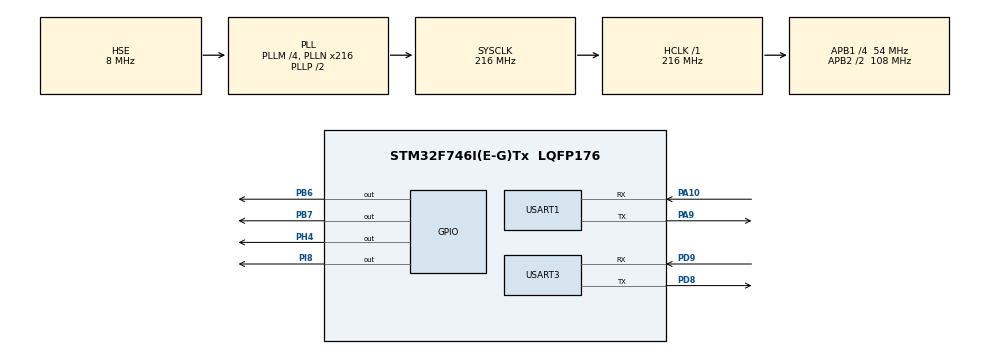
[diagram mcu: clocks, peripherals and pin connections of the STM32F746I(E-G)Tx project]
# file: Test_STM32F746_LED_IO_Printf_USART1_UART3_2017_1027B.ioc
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Mcu.Family=STM32F7
Mcu.Name=STM32F746I(E-G)Tx
Mcu.Package=LQFP176
NVIC.PriorityGroup=NVIC_PRIORITYGROUP_4
NVIC.USART3_IRQn=true\:0\:0\:false\:false\:true
PA10.Mode=Asynchronous
PA10.Signal=USART1_RX
PA9.Mode=Asynchronous
PA9.Signal=USART1_TX
PB6.Signal=GPIO_Output
PB7.Signal=GPIO_Output
PD8.Mode=Asynchronous
PD8.Signal=USART3_TX
PD9.Mode=Asynchronous
PD9.Signal=USART3_RX
PH0/OSC_IN.Mode=HSE-External-Oscillator
PH0/OSC_IN.Signal=RCC_OSC_IN
PH1/OSC_OUT.Mode=HSE-External-Oscillator
PH1/OSC_OUT.Signal=RCC_OSC_OUT
PH4.Signal=GPIO_Output
PI8.Signal=GPIO_Output
ProjectManager.HeapSize=0x200
ProjectManager.StackSize=0x400
ProjectManager.TargetToolchain=EWARM
RCC.AHBFreq_Value=216000000
RCC.APB1CLKDivider=RCC_HCLK_DIV4
RCC.APB1Freq_Value=54000000
RCC.APB1TimFreq_Value=108000000
RCC.APB2CLKDivider=RCC_HCLK_DIV2
RCC.APB2Freq_Value=108000000
RCC.APB2TimFreq_Value=216000000
RCC.CortexFreq_Value=216000000
RCC.HCLKFreq_Value=216000000
RCC.HSE_VALUE=8000000
RCC.HSI_VALUE=16000000
RCC.LSE_VALUE=32768
RCC.PLLM=4
RCC.PLLN=216
RCC.PLLSourceVirtual=RCC_PLLSOURCE_HSE
RCC.SYSCLKFreq_VALUE=216000000
RCC.SYSCLKSource=RCC_SYSCLKSOURCE_PLLCLK
RCC.USBFreq_Value=216000000
RCC.VCOOutputFreq_Value=432000000
USART1.VirtualMode-Asynchronous=VM_ASYNC
USART1.WordLength=WORDLENGTH_8B
USART3.VirtualMode-Asynchronous=VM_ASYNC
USART3.WordLength=WORDLENGTH_8B
board=Test_STM32F746_LED_IO_Printf_USART1_UART3_2017_1027B

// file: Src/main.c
/**
  ******************************************************************************
  * File Name          : main.c
  * Description        : Main program body
  ******************************************************************************
  ** This notice applies to any and all portions of this file
  * that are not between comment pairs USER CODE BEGIN and
  * USER CODE END. Other portions of this file, whether
  * inserted by the user or by software development tools
  * are owned by their respective copyright owners.
  *
  * COPYRIGHT(c) 2017 STMicroelectronics
  *
  * Redistribution and use in source and binary forms, with or without modification,
  * are permitted provided that the following conditions are met:
  *   1. Redistributions of source code must retain the above copyright notice,
  *      this list of conditions and the following disclaimer.
  *   2. Redistributions in binary form must reproduce the above copyright notice,
  *      this list of conditions and the following disclaimer in the documentation
  *      and/or other materials provided with the distribution.
  *   3. Neither the name of STMicroelectronics nor the names of its contributors
  *      may be used to endorse or promote products derived from this software
  *      without specific prior written permission.
  *
  * THIS SOFTWARE IS PROVIDED BY THE COPYRIGHT HOLDERS AND CONTRIBUTORS "AS IS"
  * AND ANY EXPRESS OR IMPLIED WARRANTIES, INCLUDING, BUT NOT LIMITED TO, THE
  * IMPLIED WARRANTIES OF MERCHANTABILITY AND FITNESS FOR A PARTICULAR PURPOSE ARE
  * DISCLAIMED. IN NO EVENT SHALL THE COPYRIGHT HOLDER OR CONTRIBUTORS BE LIABLE
  * FOR ANY DIRECT, INDIRECT, INCIDENTAL, SPECIAL, EXEMPLARY, OR CONSEQUENTIAL
  * DAMAGES (INCLUDING, BUT NOT LIMITED TO, PROCUREMENT OF SUBSTITUTE GOODS OR
  * SERVICES; LOSS OF USE, DATA, OR PROFITS; OR BUSINESS INTERRUPTION) HOWEVER
  * CAUSED AND ON ANY THEORY OF LIABILITY, WHETHER IN CONTRACT, STRICT LIABILITY,
  * OR TORT (INCLUDING NEGLIGENCE OR OTHERWISE) ARISING IN ANY WAY OUT OF THE USE
  * OF THIS SOFTWARE, EVEN IF ADVISED OF THE POSSIBILITY OF SUCH DAMAGE.
  *
  ******************************************************************************
  */
#include "main.h"
#include "stm32f7xx_hal.h"

UART_HandleTypeDef huart1;
UART_HandleTypeDef huart3;

/* USER CODE BEGIN PV */
/* Private variables ---------------------------------------------------------*/

/* USER CODE END PV */

void SystemClock_Config(void);
static void MX_GPIO_Init(void);
static void MX_USART1_UART_Init(void);
static void MX_USART3_UART_Init(void);

/* USER CODE BEGIN PFP */
/* Private function prototypes -----------------------------------------------*/

/* USER CODE END PFP */

int main(void)
{

  /* MCU Configuration----------------------------------------------------------*/

  /* Reset of all peripherals, Initializes the Flash interface and the Systick. */
  HAL_Init();

  /* Configure the system clock */
  SystemClock_Config();

  /* Initialize all configured peripherals */
  MX_GPIO_Init();
  MX_USART1_UART_Init();
  MX_USART3_UART_Init();

  /* Infinite loop */
  while (1)
  {

  /* USER CODE BEGIN 3 */
  	  #if 0		//LJH
		HAL_GPIO_TogglePin(GPIOB,GPIO_PIN_6);
		HAL_Delay(200);
		HAL_GPIO_TogglePin(GPIOB,GPIO_PIN_7);
		HAL_Delay(200);
		HAL_GPIO_TogglePin(GPIOH,GPIO_PIN_4);
		HAL_Delay(200);
		HAL_GPIO_TogglePin(GPIOI,GPIO_PIN_8);
		HAL_Delay(200);
		//printf("Hello World-LJH\r\n");
	#endif

  }
  /* USER CODE END 3 */

}

/** System Clock Configuration
*/
void SystemClock_Config(void)
{

  RCC_OscInitTypeDef RCC_OscInitStruct;
  RCC_ClkInitTypeDef RCC_ClkInitStruct;
  RCC_PeriphCLKInitTypeDef PeriphClkInitStruct;

    /**Configure the main internal regulator output voltage
    */
  __HAL_RCC_PWR_CLK_ENABLE();

  __HAL_PWR_VOLTAGESCALING_CONFIG(PWR_REGULATOR_VOLTAGE_SCALE1);

    /**Initializes the CPU, AHB and APB busses clocks
    */
  RCC_OscInitStruct.OscillatorType = RCC_OSCILLATORTYPE_HSE;
  RCC_OscInitStruct.HSEState = RCC_HSE_ON;
  RCC_OscInitStruct.PLL.PLLState = RCC_PLL_ON;
  RCC_OscInitStruct.PLL.PLLSource = RCC_PLLSOURCE_HSE;
  RCC_OscInitStruct.PLL.PLLM = 4;
  RCC_OscInitStruct.PLL.PLLN = 216;
  RCC_OscInitStruct.PLL.PLLP = RCC_PLLP_DIV2;
  RCC_OscInitStruct.PLL.PLLQ = 2;
  if (HAL_RCC_OscConfig(&RCC_OscInitStruct) != HAL_OK)
  {
    _Error_Handler(__FILE__, __LINE__);
  }

    /**Activate the Over-Drive mode
    */
  if (HAL_PWREx_EnableOverDrive() != HAL_OK)
  {
    _Error_Handler(__FILE__, __LINE__);
  }

    /**Initializes the CPU, AHB and APB busses clocks
    */
  RCC_ClkInitStruct.ClockType = RCC_CLOCKTYPE_HCLK|RCC_CLOCKTYPE_SYSCLK
                              |RCC_CLOCKTYPE_PCLK1|RCC_CLOCKTYPE_PCLK2;
  RCC_ClkInitStruct.SYSCLKSource = RCC_SYSCLKSOURCE_PLLCLK;
  RCC_ClkInitStruct.AHBCLKDivider = RCC_SYSCLK_DIV1;
  RCC_ClkInitStruct.APB1CLKDivider = RCC_HCLK_DIV4;
  RCC_ClkInitStruct.APB2CLKDivider = RCC_HCLK_DIV2;

  if (HAL_RCC_ClockConfig(&RCC_ClkInitStruct, FLASH_LATENCY_7) != HAL_OK)
  {
    _Error_Handler(__FILE__, __LINE__);
  }

  PeriphClkInitStruct.PeriphClockSelection = RCC_PERIPHCLK_USART1|RCC_PERIPHCLK_USART3;
  PeriphClkInitStruct.Usart1ClockSelection = RCC_USART1CLKSOURCE_PCLK2;
  PeriphClkInitStruct.Usart3ClockSelection = RCC_USART3CLKSOURCE_PCLK1;
  if (HAL_RCCEx_PeriphCLKConfig(&PeriphClkInitStruct) != HAL_OK)
  {
    _Error_Handler(__FILE__, __LINE__);
  }

    /**Configure the Systick interrupt time
    */
  HAL_SYSTICK_Config(HAL_RCC_GetHCLKFreq()/1000);

    /**Configure the Systick
    */
  HAL_SYSTICK_CLKSourceConfig(SYSTICK_CLKSOURCE_HCLK);

  /* SysTick_IRQn interrupt configuration */
  HAL_NVIC_SetPriority(SysTick_IRQn, 0, 0);
}

/* USART1 init function */
static void MX_USART1_UART_Init(void)
{

  huart1.Instance = USART1;
  huart1.Init.BaudRate = 115200;
  huart1.Init.WordLength = UART_WORDLENGTH_8B;
  huart1.Init.StopBits = UART_STOPBITS_1;
  huart1.Init.Parity = UART_PARITY_NONE;
  huart1.Init.Mode = UART_MODE_TX_RX;
  huart1.Init.HwFlowCtl = UART_HWCONTROL_NONE;
  huart1.Init.OverSampling = UART_OVERSAMPLING_16;
  huart1.Init.OneBitSampling = UART_ONE_BIT_SAMPLE_DISABLE;
  huart1.AdvancedInit.AdvFeatureInit = UART_ADVFEATURE_NO_INIT;
  if (HAL_UART_Init(&huart1) != HAL_OK)
  {
    _Error_Handler(__FILE__, __LINE__);
  }
  #if 1	//LJH
	 HAL_NVIC_SetPriority(USART1_IRQn, 0, 0);
   	HAL_NVIC_EnableIRQ(USART1_IRQn);
   	__HAL_UART_ENABLE_IT(&huart1,UART_IT_RXNE); // rx  on
  #endif

}

/* USART3 init function */
static void MX_USART3_UART_Init(void)
{

  huart3.Instance = USART3;
  huart3.Init.BaudRate = 115200;
  huart3.Init.WordLength = UART_WORDLENGTH_8B;
  huart3.Init.StopBits = UART_STOPBITS_1;
  huart3.Init.Parity = UART_PARITY_NONE;
  huart3.Init.Mode = UART_MODE_TX_RX;
  huart3.Init.HwFlowCtl = UART_HWCONTROL_NONE;
  huart3.Init.OverSampling = UART_OVERSAMPLING_16;
  huart3.Init.OneBitSampling = UART_ONE_BIT_SAMPLE_DISABLE;
  huart3.AdvancedInit.AdvFeatureInit = UART_ADVFEATURE_NO_INIT;
  if (HAL_UART_Init(&huart3) != HAL_OK)
  {
    _Error_Handler(__FILE__, __LINE__);
  }
 #if 1	//LJH
	 HAL_NVIC_SetPriority(USART3_IRQn, 0, 0);
   	HAL_NVIC_EnableIRQ(USART3_IRQn);
   	__HAL_UART_ENABLE_IT(&huart3,UART_IT_RXNE); // rx  on
  #endif
}

/** Configure pins as
        * Analog
        * Input
        * Output
        * EVENT_OUT
        * EXTI
*/
static void MX_GPIO_Init(void)
{

  GPIO_InitTypeDef GPIO_InitStruct;

  /* GPIO Ports Clock Enable */
  __HAL_RCC_GPIOI_CLK_ENABLE();
  __HAL_RCC_GPIOH_CLK_ENABLE();
  __HAL_RCC_GPIOD_CLK_ENABLE();
  __HAL_RCC_GPIOA_CLK_ENABLE();
  __HAL_RCC_GPIOB_CLK_ENABLE();

  /*Configure GPIO pin Output Level */
  HAL_GPIO_WritePin(GPIOI, GPIO_PIN_8, GPIO_PIN_RESET);

  /*Configure GPIO pin Output Level */
  HAL_GPIO_WritePin(GPIOH, GPIO_PIN_4, GPIO_PIN_RESET);

  /*Configure GPIO pin Output Level */
  HAL_GPIO_WritePin(GPIOB, GPIO_PIN_6|GPIO_PIN_7, GPIO_PIN_RESET);

  /*Configure GPIO pin : PI8 */
  GPIO_InitStruct.Pin = GPIO_PIN_8;
  GPIO_InitStruct.Mode = GPIO_MODE_OUTPUT_PP;
  GPIO_InitStruct.Pull = GPIO_NOPULL;
  GPIO_InitStruct.Speed = GPIO_SPEED_FREQ_LOW;
  HAL_GPIO_Init(GPIOI, &GPIO_InitStruct);

  /*Configure GPIO pin : PH4 */
  GPIO_InitStruct.Pin = GPIO_PIN_4;
  GPIO_InitStruct.Mode = GPIO_MODE_OUTPUT_PP;
  GPIO_InitStruct.Pull = GPIO_NOPULL;
  GPIO_InitStruct.Speed = GPIO_SPEED_FREQ_LOW;
  HAL_GPIO_Init(GPIOH, &GPIO_InitStruct);

  /*Configure GPIO pins : PB6 PB7 */
  GPIO_InitStruct.Pin = GPIO_PIN_6|GPIO_PIN_7;
  GPIO_InitStruct.Mode = GPIO_MODE_OUTPUT_PP;
  GPIO_InitStruct.Pull = GPIO_NOPULL;
  GPIO_InitStruct.Speed = GPIO_SPEED_FREQ_LOW;
  HAL_GPIO_Init(GPIOB, &GPIO_InitStruct);

}

void _Error_Handler(char * file, int line)
{
  while(1)
  {
  }
}

#if 1		//LJH, printf()
	#ifdef __GNUC__
	  /* With GCC/RAISONANCE, small printf (option LD Linker->Libraries->Small printf
	     set to 'Yes') calls __io_putchar() */
	  #define PUTCHAR_PROTOTYPE int __io_putchar(int ch)
	#else
	  #define PUTCHAR_PROTOTYPE int fputc(int ch, FILE *f)
	#endif /* __GNUC__ */
	/**
	  * @brief  Retargets the C library printf function to the USART.
	  * @param  None
	  * @retval None
	  */
	PUTCHAR_PROTOTYPE
	{
	  /* Place your implementation of fputc here */
	  /* e.g. write a character to the EVAL_COM1 and Loop until the end of transmission */
	  HAL_UART_Transmit(&huart1, (uint8_t *)&ch, 1, 0xFFFF);

	  return ch;
	}

#endif

/************************ (C) COPYRIGHT STMicroelectronics *****END OF FILE****/
